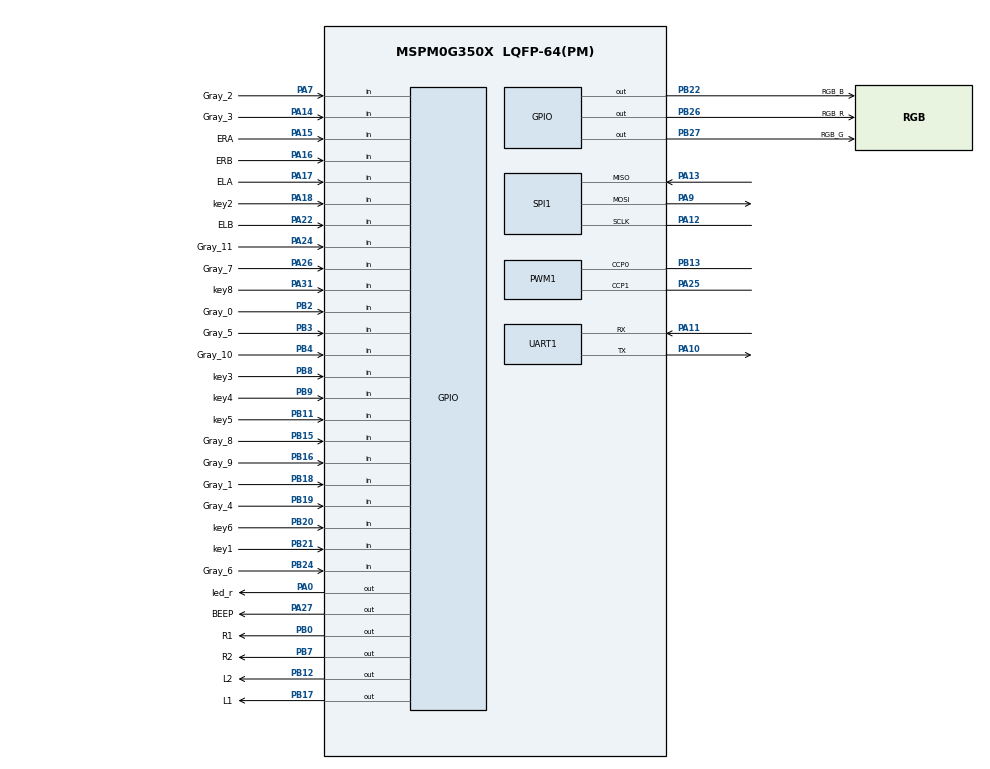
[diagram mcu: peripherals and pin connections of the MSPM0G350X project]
/**
 * @cliArgs --device "MSPM0G350X" --package "LQFP-64(PM)" --part "Default" --product "mspm0_sdk@2.00.01.00"
 * @versions {"tool":"1.20.0+3587"}
 */

/**
 * Import the modules used in this configuration.
 */
const GPIO    = scripting.addModule("/ti/driverlib/GPIO", {}, false);
const GPIO1   = GPIO.addInstance();
const GPIO2   = GPIO.addInstance();
const GPIO3   = GPIO.addInstance();
const GPIO4   = GPIO.addInstance();
const GPIO5   = GPIO.addInstance();
const GPIO6   = GPIO.addInstance();
const GPIO7   = GPIO.addInstance();
const PWM     = scripting.addModule("/ti/driverlib/PWM", {}, false);
const PWM1    = PWM.addInstance();
const SPI     = scripting.addModule("/ti/driverlib/SPI", {}, false);
const SPI1    = SPI.addInstance();
const SYSCTL  = scripting.addModule("/ti/driverlib/SYSCTL");
const SYSTICK = scripting.addModule("/ti/driverlib/SYSTICK");
const TIMER   = scripting.addModule("/ti/driverlib/TIMER", {}, false);
const TIMER1  = TIMER.addInstance();
const UART    = scripting.addModule("/ti/driverlib/UART", {}, false);
const UART1   = UART.addInstance();

/**
 * Write custom configuration values to the imported modules.
 */
const gate7  = system.clockTree["MFCLKGATE"];
gate7.enable = true;

GPIO1.$name                              = "KEY";
GPIO1.associatedPins.create(8);
GPIO1.associatedPins[0].direction        = "INPUT";
GPIO1.associatedPins[0].interruptEn      = true;
GPIO1.associatedPins[0].polarity         = "RISE";
GPIO1.associatedPins[0].$name            = "key1";
GPIO1.associatedPins[0].internalResistor = "PULL_UP";
GPIO1.associatedPins[0].assignedPort     = "PORTB";
GPIO1.associatedPins[0].assignedPin      = "21";
GPIO1.associatedPins[0].pin.$assign      = "PB21";
GPIO1.associatedPins[1].$name            = "key2";
GPIO1.associatedPins[1].direction        = "INPUT";
GPIO1.associatedPins[1].internalResistor = "PULL_DOWN";
GPIO1.associatedPins[1].assignedPort     = "PORTA";
GPIO1.associatedPins[1].assignedPin      = "18";
GPIO1.associatedPins[1].pin.$assign      = "PA18";
GPIO1.associatedPins[2].$name            = "key3";
GPIO1.associatedPins[2].direction        = "INPUT";
GPIO1.associatedPins[2].internalResistor = "PULL_UP";
GPIO1.associatedPins[2].assignedPort     = "PORTB";
GPIO1.associatedPins[2].assignedPin      = "8";
GPIO1.associatedPins[2].pin.$assign      = "PB8";
GPIO1.associatedPins[3].$name            = "key4";
GPIO1.associatedPins[3].direction        = "INPUT";
GPIO1.associatedPins[3].internalResistor = "PULL_UP";
GPIO1.associatedPins[3].assignedPort     = "PORTB";
GPIO1.associatedPins[3].assignedPin      = "9";
GPIO1.associatedPins[3].pin.$assign      = "PB9";
GPIO1.associatedPins[4].$name            = "key5";
GPIO1.associatedPins[4].direction        = "INPUT";
GPIO1.associatedPins[4].internalResistor = "PULL_UP";
GPIO1.associatedPins[4].assignedPort     = "PORTB";
GPIO1.associatedPins[4].assignedPin      = "11";
GPIO1.associatedPins[4].pin.$assign      = "PB11";
GPIO1.associatedPins[5].$name            = "key6";
GPIO1.associatedPins[5].direction        = "INPUT";
GPIO1.associatedPins[5].internalResistor = "PULL_UP";
GPIO1.associatedPins[5].assignedPort     = "PORTB";
GPIO1.associatedPins[5].assignedPin      = "20";
GPIO1.associatedPins[5].pin.$assign      = "PB20";
GPIO1.associatedPins[6].$name            = "key7";
GPIO1.associatedPins[6].direction        = "INPUT";
GPIO1.associatedPins[6].internalResistor = "PULL_UP";
GPIO1.associatedPins[6].assignedPort     = "PORTA";
GPIO1.associatedPins[6].assignedPin      = "28";
GPIO1.associatedPins[7].$name            = "key8";
GPIO1.associatedPins[7].direction        = "INPUT";
GPIO1.associatedPins[7].internalResistor = "PULL_UP";
GPIO1.associatedPins[7].assignedPort     = "PORTA";
GPIO1.associatedPins[7].assignedPin      = "31";
GPIO1.associatedPins[7].pin.$assign      = "PA31";

const Board = scripting.addModule("/ti/driverlib/Board", {}, false);

GPIO2.$name                          = "SPI_FOR_IMU_CS";
GPIO2.port                           = "PORTA";
GPIO2.associatedPins[0].$name        = "PIN_8";
GPIO2.associatedPins[0].ioStructure  = "SD";
GPIO2.associatedPins[0].initialValue = "SET";
GPIO2.associatedPins[0].assignedPin  = "8";

GPIO3.$name                          = "Motor";
GPIO3.associatedPins.create(4);
GPIO3.associatedPins[0].$name        = "L2";
GPIO3.associatedPins[0].assignedPort = "PORTB";
GPIO3.associatedPins[0].assignedPin  = "12";
GPIO3.associatedPins[0].pin.$assign  = "PB12";
GPIO3.associatedPins[1].$name        = "L1";
GPIO3.associatedPins[1].assignedPort = "PORTB";
GPIO3.associatedPins[1].assignedPin  = "17";
GPIO3.associatedPins[1].pin.$assign  = "PB17";
GPIO3.associatedPins[2].$name        = "R1";
GPIO3.associatedPins[2].assignedPort = "PORTB";
GPIO3.associatedPins[2].assignedPin  = "0";
GPIO3.associatedPins[2].pin.$assign  = "PB0";
GPIO3.associatedPins[3].$name        = "R2";
GPIO3.associatedPins[3].assignedPort = "PORTB";
GPIO3.associatedPins[3].assignedPin  = "7";
GPIO3.associatedPins[3].pin.$assign  = "PB7";

GPIO4.$name                               = "Gray";
GPIO4.associatedPins.create(12);
GPIO4.associatedPins[0].$name             = "Gray_0";
GPIO4.associatedPins[0].direction         = "INPUT";
GPIO4.associatedPins[0].internalResistor  = "PULL_UP";
GPIO4.associatedPins[0].assignedPort      = "PORTB";
GPIO4.associatedPins[0].assignedPin       = "2";
GPIO4.associatedPins[0].pin.$assign       = "PB2";
GPIO4.associatedPins[1].$name             = "Gray_1";
GPIO4.associatedPins[1].direction         = "INPUT";
GPIO4.associatedPins[1].internalResistor  = "PULL_UP";
GPIO4.associatedPins[1].assignedPort      = "PORTB";
GPIO4.associatedPins[1].assignedPin       = "18";
GPIO4.associatedPins[1].pin.$assign       = "PB18";
GPIO4.associatedPins[2].$name             = "Gray_2";
GPIO4.associatedPins[2].direction         = "INPUT";
GPIO4.associatedPins[2].internalResistor  = "PULL_UP";
GPIO4.associatedPins[2].assignedPort      = "PORTA";
GPIO4.associatedPins[2].assignedPin       = "7";
GPIO4.associatedPins[2].pin.$assign       = "PA7";
GPIO4.associatedPins[3].$name             = "Gray_3";
GPIO4.associatedPins[3].direction         = "INPUT";
GPIO4.associatedPins[3].internalResistor  = "PULL_UP";
GPIO4.associatedPins[3].assignedPort      = "PORTA";
GPIO4.associatedPins[3].assignedPin       = "14";
GPIO4.associatedPins[3].pin.$assign       = "PA14";
GPIO4.associatedPins[4].$name             = "Gray_4";
GPIO4.associatedPins[4].direction         = "INPUT";
GPIO4.associatedPins[4].assignedPort      = "PORTB";
GPIO4.associatedPins[4].assignedPin       = "19";
GPIO4.associatedPins[4].internalResistor  = "PULL_UP";
GPIO4.associatedPins[4].pin.$assign       = "PB19";
GPIO4.associatedPins[5].$name             = "Gray_5";
GPIO4.associatedPins[5].direction         = "INPUT";
GPIO4.associatedPins[5].internalResistor  = "PULL_UP";
GPIO4.associatedPins[5].assignedPort      = "PORTB";
GPIO4.associatedPins[5].assignedPin       = "3";
GPIO4.associatedPins[5].pin.$assign       = "PB3";
GPIO4.associatedPins[6].$name             = "Gray_6";
GPIO4.associatedPins[6].direction         = "INPUT";
GPIO4.associatedPins[6].internalResistor  = "PULL_UP";
GPIO4.associatedPins[6].assignedPort      = "PORTB";
GPIO4.associatedPins[6].assignedPin       = "24";
GPIO4.associatedPins[6].pin.$assign       = "PB24";
GPIO4.associatedPins[7].$name             = "Gray_7";
GPIO4.associatedPins[7].direction         = "INPUT";
GPIO4.associatedPins[7].internalResistor  = "PULL_UP";
GPIO4.associatedPins[7].assignedPort      = "PORTA";
GPIO4.associatedPins[7].assignedPin       = "26";
GPIO4.associatedPins[7].pin.$assign       = "PA26";
GPIO4.associatedPins[8].$name             = "Gray_8";
GPIO4.associatedPins[8].direction         = "INPUT";
GPIO4.associatedPins[8].internalResistor  = "PULL_UP";
GPIO4.associatedPins[8].assignedPort      = "PORTB";
GPIO4.associatedPins[8].assignedPin       = "15";
GPIO4.associatedPins[8].pin.$assign       = "PB15";
GPIO4.associatedPins[9].$name             = "Gray_9";
GPIO4.associatedPins[9].direction         = "INPUT";
GPIO4.associatedPins[9].internalResistor  = "PULL_UP";
GPIO4.associatedPins[9].assignedPort      = "PORTB";
GPIO4.associatedPins[9].assignedPin       = "16";
GPIO4.associatedPins[9].pin.$assign       = "PB16";
GPIO4.associatedPins[10].$name            = "Gray_10";
GPIO4.associatedPins[10].direction        = "INPUT";
GPIO4.associatedPins[10].internalResistor = "PULL_UP";
GPIO4.associatedPins[10].assignedPort     = "PORTB";
GPIO4.associatedPins[10].assignedPin      = "4";
GPIO4.associatedPins[10].pin.$assign      = "PB4";
GPIO4.associatedPins[11].$name            = "Gray_11";
GPIO4.associatedPins[11].direction        = "INPUT";
GPIO4.associatedPins[11].internalResistor = "PULL_UP";
GPIO4.associatedPins[11].assignedPort     = "PORTA";
GPIO4.associatedPins[11].assignedPin      = "24";
GPIO4.associatedPins[11].pin.$assign      = "PA24";

GPIO5.$name                          = "PROTA";
GPIO5.associatedPins[0].$name        = "BEEP";
GPIO5.associatedPins[0].assignedPort = "PORTA";
GPIO5.associatedPins[0].pin.$assign  = "PA27";

GPIO6.$name                          = "LED";
GPIO6.associatedPins.create(4);
GPIO6.associatedPins[0].$name        = "led_r";
GPIO6.associatedPins[0].initialValue = "SET";
GPIO6.associatedPins[0].assignedPort = "PORTA";
GPIO6.associatedPins[0].assignedPin  = "0";
GPIO6.associatedPins[0].pin.$assign  = "PA0";
GPIO6.associatedPins[1].$name        = "RGB_R";
GPIO6.associatedPins[1].assignedPort = "PORTB";
GPIO6.associatedPins[1].assignedPin  = "26";
GPIO6.associatedPins[1].pin.$assign  = "PB26";
GPIO6.associatedPins[2].$name        = "RGB_G";
GPIO6.associatedPins[2].assignedPort = "PORTB";
GPIO6.associatedPins[2].assignedPin  = "27";
GPIO6.associatedPins[2].pin.$assign  = "PB27";
GPIO6.associatedPins[3].$name        = "RGB_B";
GPIO6.associatedPins[3].assignedPort = "PORTB";
GPIO6.associatedPins[3].assignedPin  = "22";
GPIO6.associatedPins[3].pin.$assign  = "PB22";

GPIO7.$name                         = "ENCODERB";
GPIO7.port                          = "PORTA";
GPIO7.associatedPins.create(4);
GPIO7.associatedPins[0].$name       = "ELB";
GPIO7.associatedPins[0].direction   = "INPUT";
GPIO7.associatedPins[0].assignedPin = "22";
GPIO7.associatedPins[0].interruptEn = true;
GPIO7.associatedPins[0].polarity    = "RISE";
GPIO7.associatedPins[0].pin.$assign = "PA22";
GPIO7.associatedPins[1].$name       = "ELA";
GPIO7.associatedPins[1].direction   = "INPUT";
GPIO7.associatedPins[1].assignedPin = "17";
GPIO7.associatedPins[1].interruptEn = true;
GPIO7.associatedPins[1].polarity    = "RISE";
GPIO7.associatedPins[1].pin.$assign = "PA17";
GPIO7.associatedPins[2].$name       = "ERB";
GPIO7.associatedPins[2].direction   = "INPUT";
GPIO7.associatedPins[2].assignedPin = "16";
GPIO7.associatedPins[2].interruptEn = true;
GPIO7.associatedPins[2].polarity    = "RISE";
GPIO7.associatedPins[2].pin.$assign = "PA16";
GPIO7.associatedPins[3].$name       = "ERA";
GPIO7.associatedPins[3].direction   = "INPUT";
GPIO7.associatedPins[3].assignedPin = "15";
GPIO7.associatedPins[3].interruptEn = true;
GPIO7.associatedPins[3].polarity    = "RISE";
GPIO7.associatedPins[3].pin.$assign = "PA15";

PWM1.$name                              = "PWM_Motor";
PWM1.timerCount                         = 3200;
PWM1.pwmMode                            = "EDGE_ALIGN_UP";
PWM1.peripheral.$assign                 = "TIMG12";
PWM1.peripheral.ccp0Pin.$assign         = "PB13";
PWM1.peripheral.ccp1Pin.$assign         = "PA25";
PWM1.PWM_CHANNEL_0.$name                = "ti_driverlib_pwm_PWMTimerCC0";
PWM1.PWM_CHANNEL_0.dutyCycle            = 10;
PWM1.PWM_CHANNEL_1.$name                = "ti_driverlib_pwm_PWMTimerCC1";
PWM1.PWM_CHANNEL_1.dutyCycle            = 20;
PWM1.ccp0PinConfig.direction            = scripting.forceWrite("OUTPUT");
PWM1.ccp0PinConfig.hideOutputInversion  = scripting.forceWrite(false);
PWM1.ccp0PinConfig.onlyInternalResistor = scripting.forceWrite(false);
PWM1.ccp0PinConfig.passedPeripheralType = scripting.forceWrite("Digital");
PWM1.ccp0PinConfig.$name                = "ti_driverlib_gpio_GPIOPinGeneric4";
PWM1.ccp1PinConfig.direction            = scripting.forceWrite("OUTPUT");
PWM1.ccp1PinConfig.hideOutputInversion  = scripting.forceWrite(false);
PWM1.ccp1PinConfig.onlyInternalResistor = scripting.forceWrite(false);
PWM1.ccp1PinConfig.passedPeripheralType = scripting.forceWrite("Digital");
PWM1.ccp1PinConfig.$name                = "ti_driverlib_gpio_GPIOPinGeneric5";

SPI1.$name                              = "SPI_FOR_IMU";
SPI1.targetBitRate                      = 5000000;
SPI1.peripheral.$assign                 = "SPI0";
SPI1.peripheral.sclkPin.$assign         = "PA12";
SPI1.peripheral.mosiPin.$assign         = "PA9";
SPI1.peripheral.misoPin.$assign         = "PA13";
SPI1.sclkPinConfig.direction            = scripting.forceWrite("OUTPUT");
SPI1.sclkPinConfig.onlyInternalResistor = scripting.forceWrite(false);
SPI1.sclkPinConfig.passedPeripheralType = scripting.forceWrite("Digital");
SPI1.sclkPinConfig.$name                = "ti_driverlib_gpio_GPIOPinGeneric7";
SPI1.mosiPinConfig.direction            = scripting.forceWrite("OUTPUT");
SPI1.mosiPinConfig.hideOutputInversion  = scripting.forceWrite(false);
SPI1.mosiPinConfig.onlyInternalResistor = scripting.forceWrite(false);
SPI1.mosiPinConfig.passedPeripheralType = scripting.forceWrite("Digital");
SPI1.mosiPinConfig.$name                = "ti_driverlib_gpio_GPIOPinGeneric8";
SPI1.misoPinConfig.onlyInternalResistor = scripting.forceWrite(false);
SPI1.misoPinConfig.passedPeripheralType = scripting.forceWrite("Digital");
SPI1.misoPinConfig.$name                = "ti_driverlib_gpio_GPIOPinGeneric9";
SPI1.cs0PinConfig.direction             = scripting.forceWrite("OUTPUT");
SPI1.cs0PinConfig.hideOutputInversion   = scripting.forceWrite(false);
SPI1.cs0PinConfig.onlyInternalResistor  = scripting.forceWrite(false);
SPI1.cs0PinConfig.passedPeripheralType  = scripting.forceWrite("Digital");
SPI1.cs0PinConfig.$name                 = "ti_driverlib_gpio_GPIOPinGeneric10";

SYSCTL.forceDefaultClkConfig = true;
SYSCTL.clockTreeEn           = true;

SYSTICK.periodEnable      = true;
SYSTICK.interruptPriority = "0";
SYSTICK.period            = 32;
SYSTICK.systickEnable     = true;

TIMER1.$name              = "TIMER_0";
TIMER1.timerPeriod        = "10ms";
TIMER1.timerMode          = "PERIODIC";
TIMER1.timerClkDiv        = 8;
TIMER1.interrupts         = ["ZERO"];
TIMER1.peripheral.$assign = "TIMG0";

UART1.$name                    = "UART_0";
UART1.uartClkSrc               = "MFCLK";
UART1.enabledInterrupts        = ["RX"];
UART1.targetBaudRate           = 115200;
UART1.interruptPriority        = "1";
UART1.peripheral.$assign       = "UART0";
UART1.peripheral.rxPin.$assign = "PA11";
UART1.peripheral.txPin.$assign = "PA10";
UART1.txPinConfig.$name        = "ti_driverlib_gpio_GPIOPinGeneric0";
UART1.rxPinConfig.$name        = "ti_driverlib_gpio_GPIOPinGeneric1";

/**
 * Pinmux solution for unlocked pins/peripherals. This ensures that minor changes to the automatic solver in a future
 * version of the tool will not impact the pinmux you originally saw.  These lines can be completely deleted in order to
 * re-solve from scratch.
 */
GPIO1.associatedPins[6].pin.$suggestSolution = "PA28";
Board.peripheral.$suggestSolution            = "DEBUGSS";
Board.peripheral.swclkPin.$suggestSolution   = "PA20";
Board.peripheral.swdioPin.$suggestSolution   = "PA19";
GPIO2.associatedPins[0].pin.$suggestSolution = "PA8";
SPI1.peripheral.cs0Pin.$suggestSolution      = "PA2";
